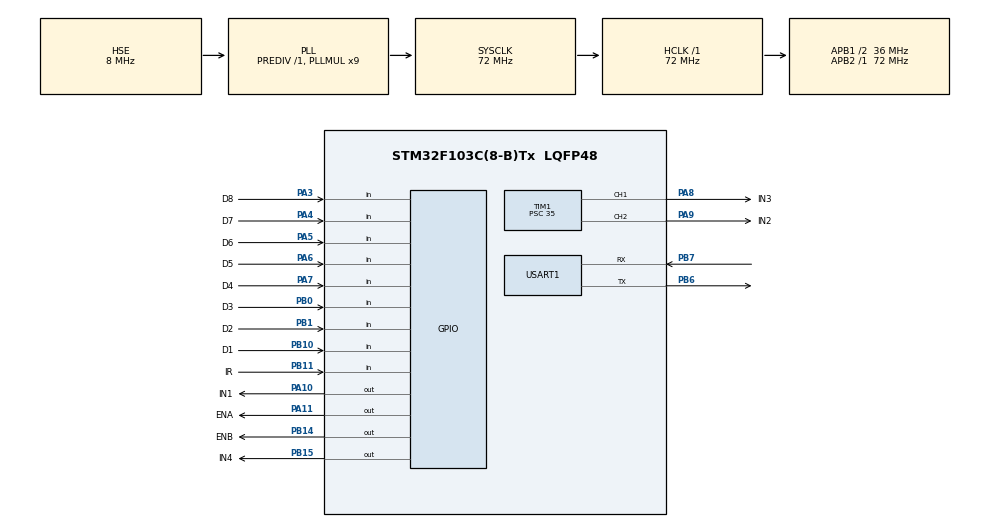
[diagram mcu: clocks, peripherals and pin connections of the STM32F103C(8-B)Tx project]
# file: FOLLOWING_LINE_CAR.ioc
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Mcu.Family=STM32F1
Mcu.Name=STM32F103C(8-B)Tx
Mcu.Package=LQFP48
NVIC.PriorityGroup=NVIC_PRIORITYGROUP_4
PA10.GPIO_Label=IN1
PA10.Signal=GPIO_Output
PA11.GPIO_Label=ENA
PA11.Signal=GPIO_Output
PA13.Mode=Serial_Wire
PA13.Signal=SYS_JTMS-SWDIO
PA14.Mode=Serial_Wire
PA14.Signal=SYS_JTCK-SWCLK
PA3.GPIO_Label=D8
PA3.Signal=GPIO_Input
PA4.GPIO_Label=D7
PA4.Signal=GPIO_Input
PA5.GPIO_Label=D6
PA5.Signal=GPIO_Input
PA6.GPIO_Label=D5
PA6.Signal=GPIO_Input
PA7.GPIO_Label=D4
PA7.Signal=GPIO_Input
PA8.GPIO_Label=IN3
PA8.Signal=S_TIM1_CH1
PA9.GPIO_Label=IN2
PA9.Signal=S_TIM1_CH2
PB0.GPIO_Label=D3
PB0.Signal=GPIO_Input
PB1.GPIO_Label=D2
PB1.Signal=GPIO_Input
PB10.GPIO_Label=D1
PB10.Signal=GPIO_Input
PB11.GPIO_Label=IR
PB11.Signal=GPIO_Input
PB14.GPIO_Label=ENB
PB14.Signal=GPIO_Output
PB15.GPIO_Label=IN4
PB15.Signal=GPIO_Output
PB6.Mode=Asynchronous
PB6.Signal=USART1_TX
PB7.Mode=Asynchronous
PB7.Signal=USART1_RX
PD0-OSC_IN.Mode=HSE-External-Oscillator
PD0-OSC_IN.Signal=RCC_OSC_IN
PD1-OSC_OUT.Mode=HSE-External-Oscillator
PD1-OSC_OUT.Signal=RCC_OSC_OUT
ProjectManager.HeapSize=0x200
ProjectManager.StackSize=0x400
ProjectManager.TargetToolchain=STM32CubeIDE
RCC.AHBFreq_Value=72000000
RCC.APB1CLKDivider=RCC_HCLK_DIV2
RCC.APB1Freq_Value=36000000
RCC.APB1TimFreq_Value=72000000
RCC.APB2Freq_Value=72000000
RCC.APB2TimFreq_Value=72000000
RCC.HCLKFreq_Value=72000000
RCC.PLLMUL=RCC_PLL_MUL9
RCC.PLLSourceVirtual=RCC_PLLSOURCE_HSE
RCC.SYSCLKFreq_VALUE=72000000
RCC.SYSCLKSource=RCC_SYSCLKSOURCE_PLLCLK
RCC.USBFreq_Value=72000000
SH.S_TIM1_CH1.0=TIM1_CH1,PWM Generation1 CH1
SH.S_TIM1_CH2.0=TIM1_CH2,PWM Generation2 CH2
TIM1.Channel-PWM\ Generation1\ CH1=TIM_CHANNEL_1
TIM1.Channel-PWM\ Generation2\ CH2=TIM_CHANNEL_2
TIM1.Period=19999
TIM1.Prescaler=35
USART1.VirtualMode=VM_ASYNC
VP_TIM1_VS_ClockSourceINT.Mode=Internal
board=custom

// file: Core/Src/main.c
/* USER CODE BEGIN Header */
/**
  ******************************************************************************
  * @file           : main.c
  * @brief          : Main program body
  ******************************************************************************
  * @attention
  *
  * Copyright (c) 2022 STMicroelectronics.
  * All rights reserved.
  *
  * This software is licensed under terms that can be found in the LICENSE file
  * in the root directory of this software component.
  * If no LICENSE file comes with this software, it is provided AS-IS.
  *
  ******************************************************************************
  */
/* USER CODE END Header */
#include "main.h"
#include "Motor.h"

TIM_HandleTypeDef htim1;

UART_HandleTypeDef huart1;

/* USER CODE BEGIN PV */
uint8_t sensorsValue[8];
/* USER CODE END PV */

void SystemClock_Config(void);
static void MX_GPIO_Init(void);
static void MX_TIM1_Init(void);
static void MX_USART1_UART_Init(void);

int main(void)
{

  /* MCU Configuration--------------------------------------------------------*/

  /* Reset of all peripherals, Initializes the Flash interface and the Systick. */
  HAL_Init();

  /* Configure the system clock */
  SystemClock_Config();

  /* Initialize all configured peripherals */
  MX_GPIO_Init();
  MX_TIM1_Init();
  MX_USART1_UART_Init();
  /* USER CODE BEGIN 2 */
  HAL_TIM_PWM_Start(&htim1, TIM_CHANNEL_1);
  HAL_TIM_PWM_Start(&htim1, TIM_CHANNEL_2);
  HAL_GPIO_WritePin(GPIOB, IR_Pin, GPIO_PIN_SET);
  /* USER CODE END 2 */

  /* Infinite loop */
  while (1)
  {

    /* USER CODE BEGIN 3 */
	  sensorsValue[0] = HAL_GPIO_ReadPin(GPIOA, D8_Pin);
	  sensorsValue[1] = HAL_GPIO_ReadPin(GPIOA, D7_Pin);
	  sensorsValue[2] = HAL_GPIO_ReadPin(GPIOA, D6_Pin);
	  sensorsValue[3] = HAL_GPIO_ReadPin(GPIOA, D5_Pin);
	  sensorsValue[4] = HAL_GPIO_ReadPin(GPIOA, D4_Pin);
	  sensorsValue[5] = HAL_GPIO_ReadPin(GPIOB, D3_Pin);
	  sensorsValue[6] = HAL_GPIO_ReadPin(GPIOB, D2_Pin);
	  sensorsValue[7] = HAL_GPIO_ReadPin(GPIOB, D1_Pin);
  }
  /* USER CODE END 3 */
}

void SystemClock_Config(void)
{
  RCC_OscInitTypeDef RCC_OscInitStruct = {0};
  RCC_ClkInitTypeDef RCC_ClkInitStruct = {0};

  /** Initializes the RCC Oscillators according to the specified parameters
  * in the RCC_OscInitTypeDef structure.
  */
  RCC_OscInitStruct.OscillatorType = RCC_OSCILLATORTYPE_HSE;
  RCC_OscInitStruct.HSEState = RCC_HSE_ON;
  RCC_OscInitStruct.HSEPredivValue = RCC_HSE_PREDIV_DIV1;
  RCC_OscInitStruct.HSIState = RCC_HSI_ON;
  RCC_OscInitStruct.PLL.PLLState = RCC_PLL_ON;
  RCC_OscInitStruct.PLL.PLLSource = RCC_PLLSOURCE_HSE;
  RCC_OscInitStruct.PLL.PLLMUL = RCC_PLL_MUL9;
  if (HAL_RCC_OscConfig(&RCC_OscInitStruct) != HAL_OK)
  {
    Error_Handler();
  }

  /** Initializes the CPU, AHB and APB buses clocks
  */
  RCC_ClkInitStruct.ClockType = RCC_CLOCKTYPE_HCLK|RCC_CLOCKTYPE_SYSCLK
                              |RCC_CLOCKTYPE_PCLK1|RCC_CLOCKTYPE_PCLK2;
  RCC_ClkInitStruct.SYSCLKSource = RCC_SYSCLKSOURCE_PLLCLK;
  RCC_ClkInitStruct.AHBCLKDivider = RCC_SYSCLK_DIV1;
  RCC_ClkInitStruct.APB1CLKDivider = RCC_HCLK_DIV2;
  RCC_ClkInitStruct.APB2CLKDivider = RCC_HCLK_DIV1;

  if (HAL_RCC_ClockConfig(&RCC_ClkInitStruct, FLASH_LATENCY_2) != HAL_OK)
  {
    Error_Handler();
  }
}

static void MX_TIM1_Init(void)
{

  TIM_ClockConfigTypeDef sClockSourceConfig = {0};
  TIM_MasterConfigTypeDef sMasterConfig = {0};
  TIM_OC_InitTypeDef sConfigOC = {0};
  TIM_BreakDeadTimeConfigTypeDef sBreakDeadTimeConfig = {0};

  htim1.Instance = TIM1;
  htim1.Init.Prescaler = 35;
  htim1.Init.CounterMode = TIM_COUNTERMODE_UP;
  htim1.Init.Period = 19999;
  htim1.Init.ClockDivision = TIM_CLOCKDIVISION_DIV1;
  htim1.Init.RepetitionCounter = 0;
  htim1.Init.AutoReloadPreload = TIM_AUTORELOAD_PRELOAD_DISABLE;
  if (HAL_TIM_Base_Init(&htim1) != HAL_OK)
  {
    Error_Handler();
  }
  sClockSourceConfig.ClockSource = TIM_CLOCKSOURCE_INTERNAL;
  if (HAL_TIM_ConfigClockSource(&htim1, &sClockSourceConfig) != HAL_OK)
  {
    Error_Handler();
  }
  if (HAL_TIM_PWM_Init(&htim1) != HAL_OK)
  {
    Error_Handler();
  }
  sMasterConfig.MasterOutputTrigger = TIM_TRGO_RESET;
  sMasterConfig.MasterSlaveMode = TIM_MASTERSLAVEMODE_DISABLE;
  if (HAL_TIMEx_MasterConfigSynchronization(&htim1, &sMasterConfig) != HAL_OK)
  {
    Error_Handler();
  }
  sConfigOC.OCMode = TIM_OCMODE_PWM1;
  sConfigOC.Pulse = 0;
  sConfigOC.OCPolarity = TIM_OCPOLARITY_HIGH;
  sConfigOC.OCNPolarity = TIM_OCNPOLARITY_HIGH;
  sConfigOC.OCFastMode = TIM_OCFAST_DISABLE;
  sConfigOC.OCIdleState = TIM_OCIDLESTATE_RESET;
  sConfigOC.OCNIdleState = TIM_OCNIDLESTATE_RESET;
  if (HAL_TIM_PWM_ConfigChannel(&htim1, &sConfigOC, TIM_CHANNEL_1) != HAL_OK)
  {
    Error_Handler();
  }
  if (HAL_TIM_PWM_ConfigChannel(&htim1, &sConfigOC, TIM_CHANNEL_2) != HAL_OK)
  {
    Error_Handler();
  }
  sBreakDeadTimeConfig.OffStateRunMode = TIM_OSSR_DISABLE;
  sBreakDeadTimeConfig.OffStateIDLEMode = TIM_OSSI_DISABLE;
  sBreakDeadTimeConfig.LockLevel = TIM_LOCKLEVEL_OFF;
  sBreakDeadTimeConfig.DeadTime = 0;
  sBreakDeadTimeConfig.BreakState = TIM_BREAK_DISABLE;
  sBreakDeadTimeConfig.BreakPolarity = TIM_BREAKPOLARITY_HIGH;
  sBreakDeadTimeConfig.AutomaticOutput = TIM_AUTOMATICOUTPUT_DISABLE;
  if (HAL_TIMEx_ConfigBreakDeadTime(&htim1, &sBreakDeadTimeConfig) != HAL_OK)
  {
    Error_Handler();
  }
  HAL_TIM_MspPostInit(&htim1);

}

static void MX_USART1_UART_Init(void)
{

  huart1.Instance = USART1;
  huart1.Init.BaudRate = 115200;
  huart1.Init.WordLength = UART_WORDLENGTH_8B;
  huart1.Init.StopBits = UART_STOPBITS_1;
  huart1.Init.Parity = UART_PARITY_NONE;
  huart1.Init.Mode = UART_MODE_TX_RX;
  huart1.Init.HwFlowCtl = UART_HWCONTROL_NONE;
  huart1.Init.OverSampling = UART_OVERSAMPLING_16;
  if (HAL_UART_Init(&huart1) != HAL_OK)
  {
    Error_Handler();
  }

}

static void MX_GPIO_Init(void)
{
  GPIO_InitTypeDef GPIO_InitStruct = {0};

  /* GPIO Ports Clock Enable */
  __HAL_RCC_GPIOD_CLK_ENABLE();
  __HAL_RCC_GPIOA_CLK_ENABLE();
  __HAL_RCC_GPIOB_CLK_ENABLE();

  /*Configure GPIO pin Output Level */
  HAL_GPIO_WritePin(GPIOB, ENB_Pin|IN4_Pin, GPIO_PIN_RESET);

  /*Configure GPIO pin Output Level */
  HAL_GPIO_WritePin(GPIOA, IN1_Pin|ENA_Pin, GPIO_PIN_RESET);

  /*Configure GPIO pins : D8_Pin D7_Pin D6_Pin D5_Pin
                           D4_Pin */
  GPIO_InitStruct.Pin = D8_Pin|D7_Pin|D6_Pin|D5_Pin
                          |D4_Pin;
  GPIO_InitStruct.Mode = GPIO_MODE_INPUT;
  GPIO_InitStruct.Pull = GPIO_NOPULL;
  HAL_GPIO_Init(GPIOA, &GPIO_InitStruct);

  /*Configure GPIO pins : D3_Pin D2_Pin D1_Pin IR_Pin */
  GPIO_InitStruct.Pin = D3_Pin|D2_Pin|D1_Pin|IR_Pin;
  GPIO_InitStruct.Mode = GPIO_MODE_INPUT;
  GPIO_InitStruct.Pull = GPIO_NOPULL;
  HAL_GPIO_Init(GPIOB, &GPIO_InitStruct);

  /*Configure GPIO pins : ENB_Pin IN4_Pin */
  GPIO_InitStruct.Pin = ENB_Pin|IN4_Pin;
  GPIO_InitStruct.Mode = GPIO_MODE_OUTPUT_PP;
  GPIO_InitStruct.Pull = GPIO_NOPULL;
  GPIO_InitStruct.Speed = GPIO_SPEED_FREQ_LOW;
  HAL_GPIO_Init(GPIOB, &GPIO_InitStruct);

  /*Configure GPIO pins : IN1_Pin ENA_Pin */
  GPIO_InitStruct.Pin = IN1_Pin|ENA_Pin;
  GPIO_InitStruct.Mode = GPIO_MODE_OUTPUT_PP;
  GPIO_InitStruct.Pull = GPIO_NOPULL;
  GPIO_InitStruct.Speed = GPIO_SPEED_FREQ_LOW;
  HAL_GPIO_Init(GPIOA, &GPIO_InitStruct);

}

void Error_Handler(void)
{
  __disable_irq();
  while (1)
  {
  }
}
